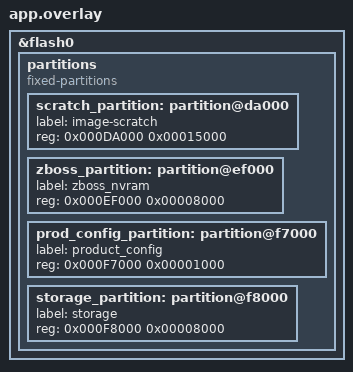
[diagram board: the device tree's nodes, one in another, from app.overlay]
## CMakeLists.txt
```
#
# Copyright (c) 2020 Nordic Semiconductor ASA
#
# SPDX-License-Identifier: LicenseRef-BSD-5-Clause-Nordic
#

cmake_minimum_required(VERSION 3.8)

add_definitions(-DZB_ED_ROLE)

include($ENV{ZEPHYR_BASE}/../nrf/cmake/boilerplate.cmake)
include($ENV{ZEPHYR_BASE}/cmake/app/boilerplate.cmake NO_POLICY_SCOPE)

project("Light Switch")

# NORDIC SDK APP START
target_sources(
  app PRIVATE src/main.c
)
target_sources_ifdef(CONFIG_NUS_CMD
  app PRIVATE src/nus_cmd.c
)
target_include_directories(app PRIVATE include)
# NORDIC SDK APP END
```

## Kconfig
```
#
# Copyright (c) 2020 Nordic Semiconductor ASA
#
# SPDX-License-Identifier: LicenseRef-BSD-5-Clause-Nordic
#

config NUS_CMD
	bool "Enable NUS command service"
	select BT
	select BT_SMP
	select BT_PERIPHERAL
	select BT_GATT_NUS
	select BT_SETTINGS
	select SETTINGS
	help
	  NUS command service

if NUS_CMD_SERVICE

module = NUS_CMD
module-str = NUS command
source "${ZEPHYR_BASE}/subsys/logging/Kconfig.template.log_config"

endif

menu "Zephyr Kernel"
source "Kconfig.zephyr"
endmenu
```

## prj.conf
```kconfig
#
# Copyright (c) 2020 Nordic Semiconductor ASA
#
# SPDX-License-Identifier: LicenseRef-BSD-5-Clause-Nordic
#

CONFIG_NCS_SAMPLES_DEFAULTS=y

CONFIG_UART_INTERRUPT_DRIVEN=y
CONFIG_SERIAL=y
CONFIG_GPIO=y

# Make sure printk is not printing to the UART console
CONFIG_CONSOLE=y
CONFIG_UART_CONSOLE=y

CONFIG_HEAP_MEM_POOL_SIZE=2048

CONFIG_ZIGBEE=y
CONFIG_ZIGBEE_ROLE_END_DEVICE=y

# Enable DK LED and Buttons library
CONFIG_DK_LIBRARY=y

# This example requires more workqueue stack
CONFIG_SYSTEM_WORKQUEUE_STACK_SIZE=2048

# Cryptocell is not supported through CSPRNG driver API: NCSDK-4813
CONFIG_ENTROPY_CC310=n
```

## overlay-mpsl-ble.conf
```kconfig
# Enable NUS command service
CONFIG_NUS_CMD=y

# BLE configuration
CONFIG_BT_DEVICE_NAME="Zigbee_Switch"
CONFIG_BT_DEVICE_APPEARANCE=833
CONFIG_BT_MAX_CONN=1
CONFIG_BT_MAX_PAIRED=1

# Enable multiprotocol
CONFIG_BT_LL_NRFXLIB_DEFAULT=y
```

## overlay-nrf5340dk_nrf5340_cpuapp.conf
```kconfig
#
# Copyright (c) 2020 Nordic Semiconductor ASA
#
# SPDX-License-Identifier: LicenseRef-BSD-5-Clause-Nordic
#
CONFIG_MAIN_STACK_SIZE=2048
CONFIG_MPSL=n

CONFIG_CRYPTO=n
CONFIG_CRYPTO_NRF_ECB=n
CONFIG_ENTROPY_CC3XX=y

CONFIG_TINYCRYPT=y
CONFIG_CTR_DRBG_CSPRNG_GENERATOR=y
CONFIG_ZIGBEE_USE_SOFTWARE_AES=y
```

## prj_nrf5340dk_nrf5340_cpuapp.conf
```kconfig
#
# Copyright (c) 2020 Nordic Semiconductor ASA
#
# SPDX-License-Identifier: LicenseRef-BSD-5-Clause-Nordic
#

CONFIG_NCS_SAMPLES_DEFAULTS=y

CONFIG_UART_INTERRUPT_DRIVEN=y
CONFIG_SERIAL=y
CONFIG_GPIO=y

# Make sure printk is not printing to the UART console
CONFIG_CONSOLE=y
CONFIG_UART_CONSOLE=y

CONFIG_HEAP_MEM_POOL_SIZE=2048
CONFIG_MAIN_STACK_SIZE=2048

CONFIG_ZIGBEE=y
CONFIG_ZIGBEE_ROLE_END_DEVICE=y

# Enable bonding
CONFIG_NVS=y

# Enable DK LED and Buttons library
CONFIG_DK_LIBRARY=y

# This example requires more workqueue stack
CONFIG_SYSTEM_WORKQUEUE_STACK_SIZE=2048

# Use software cryptography on nRF5340
CONFIG_TINYCRYPT=y
CONFIG_CTR_DRBG_CSPRNG_GENERATOR=y
CONFIG_ZIGBEE_USE_SOFTWARE_AES=y

# Enable API for powering down unused RAM parts
CONFIG_RAM_POWER_DOWN_LIBRARY=y

#Networking
CONFIG_MPSL=n
```

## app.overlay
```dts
/* Copyright (c) 2020 Nordic Semiconductor ASA
 *
 * SPDX-License-Identifier: Apache-2.0
 */

 /delete-node/ &scratch_partition;
 /delete-node/ &storage_partition;

 &flash0 {
	partitions {
		compatible = "fixed-partitions";
		#address-cells = <1>;
		#size-cells = <1>;

		scratch_partition: partition@da000 {
			label = "image-scratch";
			reg = <0x000DA000 0x00015000>;
		};
		zboss_partition: partition@ef000 {
			label = "zboss_nvram";
			reg = <0x000EF000 0x00008000>;
		};
		prod_config_partition: partition@f7000 {
			label = "product_config";
			reg = <0x000F7000 0x00001000>;
		};
		storage_partition: partition@f8000 {
			label = "storage";
			reg = <0x000F8000 0x00008000>;
		};
	};
};
```

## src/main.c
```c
/*
 * Copyright (c) 2020 Nordic Semiconductor ASA
 *
 * SPDX-License-Identifier: LicenseRef-BSD-5-Clause-Nordic
 */

/** @file
 * @brief Dimmer switch for HA profile implementation.
 */

#include <zephyr.h>
#include <device.h>
#include <logging/log.h>
#include <settings/settings.h>
#include <dk_buttons_and_leds.h>

#include <zboss_api.h>
#include <zboss_api_addons.h>
#include <zigbee_helpers.h>
#include <zb_error_handler.h>
#include <zb_nrf_platform.h>
#include "zb_mem_config_custom.h"

#if CONFIG_NUS_CMD
#include "nus_cmd.h"

/* LED which indicates that Central is connected */
#define NUS_STATUS_LED            DK_LED1
/* UART command that will turn on found light bulb(s). */
#define COMMAND_ON                "n"
/**< UART command that will turn off found light bulb(s). */
#define COMMAND_OFF               "f"
/**< UART command that will turn toggle found light bulb(s). */
#define COMMAND_TOGGLE            "t"
/**< UART command that will increase brightness of found light bulb(s). */
#define COMMAND_INCREASE          "i"
/**< UART command that will decrease brightness of found light bulb(s). */
#define COMMAND_DECREASE          "d"
#endif

/* Source endpoint used to control light bulb. */
#define LIGHT_SWITCH_ENDPOINT      1
/* Delay between the light switch startup and light bulb finding procedure. */
#define MATCH_DESC_REQ_START_DELAY (2 * ZB_TIME_ONE_SECOND)
/* Timeout for finding procedure. */
#define MATCH_DESC_REQ_TIMEOUT     (5 * ZB_TIME_ONE_SECOND)
/* Find only non-sleepy device. */
#define MATCH_DESC_REQ_ROLE        ZB_NWK_BROADCAST_RX_ON_WHEN_IDLE

/* Do not erase NVRAM to save the network parameters after device reboot or
 * power-off. NOTE: If this option is set to ZB_TRUE then do full device erase
 * for all network devices before running other samples.
 */
#define ERASE_PERSISTENT_CONFIG    ZB_FALSE
/* LED indicating that light switch successfully joind Zigbee network. */
#define ZIGBEE_NETWORK_STATE_LED   DK_LED3
/* LED indicating that light witch found a light bulb to control. */
#define BULB_FOUND_LED             DK_LED4
/* Button ID used to switch on the light bulb. */
#define BUTTON_ON                  DK_BTN1_MSK
/* Button ID used to switch off the light bulb. */
#define BUTTON_OFF                 DK_BTN2_MSK
/* Dim step size - increases/decreses current level (range 0x000 - 0xfe). */
#define DIMM_STEP                  15

/* Transition time for a single step operation in 0.1 sec units.
 * 0xFFFF - immediate change.
 */
#define DIMM_TRANSACTION_TIME      2

/* Time after which the button state is checked again to detect button hold,
 * the dimm command is sent again.
 */
#define BUTTON_LONG_POLL_TMO   ZB_MILLISECONDS_TO_BEACON_INTERVAL(500)

#if !defined ZB_ED_ROLE
#error Define ZB_ED_ROLE to compile light switch (End Device) source code.
#endif

LOG_MODULE_REGISTER(app);

struct light_switch_bulb_params {
	zb_uint8_t  endpoint;
	zb_uint16_t short_addr;
};

struct light_switch_button {
	atomic_t in_progress;
	atomic_t long_poll;
};

struct light_switch_ctx {
	struct light_switch_bulb_params bulb_params;
	struct light_switch_button      button;
};

static struct light_switch_ctx device_ctx;
static zb_uint8_t  attr_zcl_version = ZB_ZCL_VERSION;
static zb_uint8_t  attr_power_source = ZB_ZCL_BASIC_POWER_SOURCE_UNKNOWN;
static zb_uint16_t attr_identify_time;

/* Declare attribute list for Basic cluster. */
ZB_ZCL_DECLARE_BASIC_ATTRIB_LIST(basic_attr_list, &attr_zcl_version,
				 &attr_power_source);

/* Declare attribute list for Identify cluster. */
ZB_ZCL_DECLARE_IDENTIFY_ATTRIB_LIST(identify_attr_list, &attr_identify_time);

/* Declare cluster list for Dimmer Switch device (Identify, Basic, Scenes,
 * Groups, On Off, Level Control).
 * Only clusters Identify and Basic have attributes.
 */
ZB_HA_DECLARE_DIMMER_SWITCH_CLUSTER_LIST(dimmer_switch_clusters,
					 basic_attr_list,
					 identify_attr_list);

/* Declare endpoint for Dimmer Switch device. */
ZB_HA_DECLARE_DIMMER_SWITCH_EP(dimmer_switch_ep,
			       LIGHT_SWITCH_ENDPOINT,
			       dimmer_switch_clusters);

/* Declare application's device context (list of registered endpoints)
 * for Dimmer Switch device.
 */
ZB_HA_DECLARE_DIMMER_SWITCH_CTX(dimmer_switch_ctx, dimmer_switch_ep);

/* Forward declarations */
static void light_switch_button_handler(zb_uint8_t button);
static void find_light_bulb(zb_bufid_t bufid);
static void find_light_bulb_timeout(zb_bufid_t bufid);
static void light_switch_send_on_off(zb_bufid_t bufid, zb_uint16_t on_off);


/**@brief Callback for button events.
 *
 * @param[in]   button_state  Bitmask containing buttons state.
 * @param[in]   has_changed   Bitmask containing buttons that has
 *                            changed their state.
 */
static void button_handler(u32_t button_state, u32_t has_changed)
{
	zb_bool_t on_off;
	zb_ret_t zb_err_code;

	/* Inform default signal handler about user input at the device. */
	user_input_indicate();

	if (device_ctx.bulb_params.short_addr == 0xFFFF) {
		LOG_DBG("No bulb found yet.");
		return;
	}

	switch (has_changed) {
	case BUTTON_ON:
		LOG_DBG("ON - button changed");
		on_off = ZB_TRUE;
		break;
	case BUTTON_OFF:
		LOG_DBG("OFF - button changed");
		on_off = ZB_FALSE;
		break;
	default:
		LOG_DBG("Unhandled button");
		return;
	}

	switch (button_state) {
	case BUTTON_ON:
	case BUTTON_OFF:
		LOG_DBG("Button pressed");
		atomic_set(&device_ctx.button.in_progress, ZB_TRUE);
		zb_err_code = zigbee_schedule_alarm(light_switch_button_handler,
						    button_state,
						    BUTTON_LONG_POLL_TMO);
		if (zb_err_code == RET_OVERFLOW) {
			LOG_WRN("Can't schedule another alarm, queue is full.");
			atomic_set(&device_ctx.button.in_progress, ZB_FALSE);
		} else {
			ZB_ERROR_CHECK(zb_err_code);
		}
		break;
	case 0:
		LOG_DBG("Button released");

		ZB_SCHEDULE_APP_ALARM_CANCEL(light_switch_button_handler,
					     ZB_ALARM_ANY_PARAM);
		atomic_set(&device_ctx.button.in_progress, ZB_FALSE);

		if (atomic_set(&device_ctx.button.long_poll, ZB_FALSE)
		    == ZB_FALSE) {
			/* Allocate output buffer and send on/off command. */
			zb_err_code = zb_buf_get_out_delayed_ext(
				light_switch_send_on_off, on_off, 0);
			ZB_ERROR_CHECK(zb_err_code);
		}
	}
}



/**@brief Function for initializing LEDs and Buttons. */
static void configure_gpio(void)
{
	int err;

	err = dk_buttons_init(button_handler);
	if (err) {
		LOG_ERR("Cannot init buttons (err: %d)", err);
	}

	err = dk_leds_init();
	if (err) {
		LOG_ERR("Cannot init LEDs (err: %d)", err);
	}
}

/**@brief Function for sending ON/OFF requests to the light bulb.
 *
 * @param[in]   bufid    Non-zero reference to Zigbee stack buffer that will be
 *                       used to construct on/off request.
 * @param[in]   on_off   Requested state of the light bulb.
 */
static void light_switch_send_on_off(zb_bufid_t bufid, zb_uint16_t cmd_id)
{
	LOG_INF("Send ON/OFF command: %d", cmd_id);

	ZB_ZCL_ON_OFF_SEND_REQ(bufid,
			       device_ctx.bulb_params.short_addr,
			       ZB_APS_ADDR_MODE_16_ENDP_PRESENT,
			       device_ctx.bulb_params.endpoint,
			       LIGHT_SWITCH_ENDPOINT,
			       ZB_AF_HA_PROFILE_ID,
			       ZB_ZCL_DISABLE_DEFAULT_RESPONSE,
			       cmd_id,
			       NULL);

}

/**@brief Function for sending step requests to the light bulb.
 *
 * @param[in]   bufid        Non-zero reference to Zigbee stack buffer that
 *                           will be used to construct step request.
 * @param[in]   is_step_up   Boolean parameter selecting direction
 *                           of step change.
 */
static void light_switch_send_step(zb_bufid_t bufid, zb_uint16_t is_step_up)
{
	u8_t step_dir = is_step_up ? ZB_ZCL_LEVEL_CONTROL_STEP_MODE_UP :
			ZB_ZCL_LEVEL_CONTROL_STEP_MODE_DOWN;

	LOG_INF("Send step level command: %d", is_step_up);

	ZB_ZCL_LEVEL_CONTROL_SEND_STEP_REQ(bufid,
					   device_ctx.bulb_params.short_addr,
					   ZB_APS_ADDR_MODE_16_ENDP_PRESENT,
					   device_ctx.bulb_params.endpoint,
					   LIGHT_SWITCH_ENDPOINT,
					   ZB_AF_HA_PROFILE_ID,
					   ZB_ZCL_DISABLE_DEFAULT_RESPONSE,
					   NULL,
					   step_dir,
					   DIMM_STEP,
					   DIMM_TRANSACTION_TIME);
}

/**@brief Callback function receiving finding procedure results.
 *
 * @param[in]   bufid   Reference to Zigbee stack buffer used to pass
 *                      received data.
 */
static void find_light_bulb_cb(zb_bufid_t bufid)
{
	/* Get the beginning of the response. */
	zb_zdo_match_desc_resp_t *resp =
			       (zb_zdo_match_desc_resp_t *) zb_buf_begin(bufid);
	/* Get the pointer to the parameters buffer, which stores APS layer
	 * response.
	 */
	zb_apsde_data_indication_t *ind  = ZB_BUF_GET_PARAM(bufid,
						    zb_apsde_data_indication_t);
	zb_uint8_t *match_ep;

	if ((resp->status == ZB_ZDP_STATUS_SUCCESS) &&
		(resp->match_len > 0) &&
		(device_ctx.bulb_params.short_addr == 0xFFFF)) {

		/* Match EP list follows right after response header */
		match_ep = (zb_uint8_t *)(resp + 1);

		/* We are searching for exact cluster, so only 1 EP
		 * may be found.
		 */
		device_ctx.bulb_params.endpoint   = *match_ep;
		device_ctx.bulb_params.short_addr = ind->src_addr;

		LOG_INF("Found bulb addr: %d ep: %d",
			device_ctx.bulb_params.short_addr,
			device_ctx.bulb_params.endpoint);

		zb_ret_t zb_err_code = ZB_SCHEDULE_APP_ALARM_CANCEL(
			find_light_bulb_timeout, ZB_ALARM_ANY_PARAM);
		ZB_ERROR_CHECK(zb_err_code);

		dk_set_led_on(BULB_FOUND_LED);
	}

	if (bufid) {
		zb_buf_free(bufid);
	}
}

/**@brief Function for sending ON/OFF and Level Control find request.
 *
 * @param[in]   bufid   Non-zero reference to Zigbee stack buffer that will be
 *                      used to construct find request.
 */
static void find_light_bulb(zb_bufid_t bufid)
{
	zb_zdo_match_desc_param_t *req;

	/* Initialize pointers inside buffer and reserve space for
	 * zb_zdo_match_desc_param_t request.
	 */
	req = zb_buf_initial_alloc(bufid,
		sizeof(zb_zdo_match_desc_param_t) + (1) * sizeof(zb_uint16_t));

	req->nwk_addr         = MATCH_DESC_REQ_ROLE;
	req->addr_of_interest = MATCH_DESC_REQ_ROLE;
	req->profile_id       = ZB_AF_HA_PROFILE_ID;

	/* We are searching for 2 clusters: On/Off and Level Control Server */
	req->num_in_clusters  = 2;
	req->num_out_clusters = 0;
	req->cluster_list[0]  = ZB_ZCL_CLUSTER_ID_ON_OFF;
	req->cluster_list[1]  = ZB_ZCL_CLUSTER_ID_LEVEL_CONTROL;

	/* Set 0xFFFF to reset short address in order to parse
	 * only one response.
	 */
	device_ctx.bulb_params.short_addr = 0xFFFF;
	(void)zb_zdo_match_desc_req(bufid, find_light_bulb_cb);
}

/**@brief Finding procedure timeout handler.
 *
 * @param[in]   bufid   Reference to Zigbee stack buffer that will be used to
 *                      construct find request.
 */
static void find_light_bulb_timeout(zb_bufid_t bufid)
{
	zb_ret_t zb_err_code;

	if (bufid) {
		LOG_INF("Bulb not found, try again");

		zb_err_code = zigbee_schedule_alarm(find_light_bulb, bufid,
						    MATCH_DESC_REQ_START_DELAY);
		ZB_ERROR_CHECK(zb_err_code);
		zb_err_code = zigbee_schedule_alarm(find_light_bulb_timeout, 0,
							MATCH_DESC_REQ_TIMEOUT);
		ZB_ERROR_CHECK(zb_err_code);
	} else {
		zb_err_code = zb_buf_get_out_delayed(find_light_bulb_timeout);
		ZB_ERROR_CHECK(zb_err_code);
	}
}

/**@brief Callback for detecting button press duration.
 *
 * @param[in]   button   BSP Button that was pressed.
 */
static void light_switch_button_handler(zb_uint8_t button)
{
	zb_ret_t zb_err_code;
	zb_bool_t on_off;

	if (dk_get_buttons() & button) {
		atomic_set(&device_ctx.button.long_poll, ZB_TRUE);
		on_off = (button == BUTTON_ON) ? ZB_TRUE : ZB_FALSE;

		/* Allocate output buffer and send step command. */
		zb_err_code = zb_buf_get_out_delayed_ext(light_switch_send_step,
							 on_off, 0);
		ZB_ERROR_CHECK(zb_err_code);

		zb_err_code = zigbee_schedule_alarm(light_switch_button_handler,
						    button,
						    BUTTON_LONG_POLL_TMO);
		if (zb_err_code == RET_OVERFLOW) {
			LOG_WRN("Can't schedule another alarm, queue is full.");
			atomic_set(&device_ctx.button.in_progress, ZB_FALSE);
		} else {
			ZB_ERROR_CHECK(zb_err_code);
		}
	} else {
		atomic_set(&device_ctx.button.long_poll, ZB_FALSE);
	}
}

/**@brief Zigbee stack event handler.
 *
 * @param[in]   bufid   Reference to the Zigbee stack buffer
 *                      used to pass signal.
 */
void zboss_signal_handler(zb_bufid_t bufid)
{
	zb_zdo_app_signal_hdr_t    *sig_hndler = NULL;
	zb_zdo_app_signal_type_t    sig = zb_get_app_signal(bufid, &sig_hndler);
	zb_ret_t                    status = ZB_GET_APP_SIGNAL_STATUS(bufid);
	zb_ret_t                    zb_err_code;

	/* Update network status LED */
	zigbee_led_status_update(bufid, ZIGBEE_NETWORK_STATE_LED);

	switch (sig) {
	case ZB_BDB_SIGNAL_DEVICE_REBOOT:
	/* fall-through */
	case ZB_BDB_SIGNAL_STEERING:
		/* Call default signal handler. */
		ZB_ERROR_CHECK(zigbee_default_signal_handler(bufid));
		if (status == RET_OK) {
			/* Check the light device address */
			if (device_ctx.bulb_params.short_addr == 0xFFFF) {
				zb_err_code = zigbee_schedule_alarm(
					find_light_bulb, bufid,
					MATCH_DESC_REQ_START_DELAY);
				ZB_ERROR_CHECK(zb_err_code);
				zb_err_code = zigbee_schedule_alarm(
					find_light_bulb_timeout, 0,
					MATCH_DESC_REQ_TIMEOUT);
				ZB_ERROR_CHECK(zb_err_code);
				/* Do not free buffer - it will be reused by
				 * find_light_bulb callback.
				 */
				bufid = 0;
			}
		}
		break;
	default:
		/* Call default signal handler. */
		ZB_ERROR_CHECK(zigbee_default_signal_handler(bufid));
		break;
	}

	if (bufid) {
		zb_buf_free(bufid);
	}
}

#if CONFIG_NUS_CMD

static void turn_on_cmd(struct k_work *item)
{
	ARG_UNUSED(item);
	zb_buf_get_out_delayed_ext(light_switch_send_on_off,
				   ZB_ZCL_CMD_ON_OFF_ON_ID, 0);
}

static void turn_off_cmd(struct k_work *item)
{
	ARG_UNUSED(item);
	zb_buf_get_out_delayed_ext(light_switch_send_on_off,
				   ZB_ZCL_CMD_ON_OFF_OFF_ID, 0);
}

static void toggle_cmd(struct k_work *item)
{
	ARG_UNUSED(item);
	zb_buf_get_out_delayed_ext(light_switch_send_on_off,
				   ZB_ZCL_CMD_ON_OFF_TOGGLE_ID, 0);
}

static void increase_cmd(struct k_work *item)
{
	ARG_UNUSED(item);
	zb_buf_get_out_delayed_ext(light_switch_send_step,
				   ZB_ZCL_LEVEL_CONTROL_STEP_MODE_UP, 0);
}

static void decrease_cmd(struct k_work *item)
{
	ARG_UNUSED(item);
	zb_buf_get_out_delayed_ext(light_switch_send_step,
				   ZB_ZCL_LEVEL_CONTROL_STEP_MODE_DOWN, 0);
}

static void on_nus_connect(struct k_work *item)
{
	ARG_UNUSED(item);
	dk_set_led_on(NUS_STATUS_LED);
}

static void on_nus_disconnect(struct k_work *item)
{
	ARG_UNUSED(item);
	dk_set_led_off(NUS_STATUS_LED);
}

static nus_entry_t commands[] = {
	NUS_COMMAND(COMMAND_ON, turn_on_cmd),
	NUS_COMMAND(COMMAND_OFF, turn_off_cmd),
	NUS_COMMAND(COMMAND_TOGGLE, toggle_cmd),
	NUS_COMMAND(COMMAND_INCREASE, increase_cmd),
	NUS_COMMAND(COMMAND_DECREASE, decrease_cmd),
	NUS_COMMAND(NULL, NULL),
};

#endif

void main(void)
{
	LOG_INF("Starting ZBOSS Light Switch example");

	/* Initialize. */
	configure_gpio();

	zigbee_erase_persistent_storage(ERASE_PERSISTENT_CONFIG);
	zb_set_ed_timeout(ED_AGING_TIMEOUT_64MIN);
	zb_set_keepalive_timeout(ZB_MILLISECONDS_TO_BEACON_INTERVAL(3000));

	/* Initialize application context structure. */
	memset(&device_ctx, 0, sizeof(struct light_switch_ctx));

	/* Set default bulb short_addr. */
	device_ctx.bulb_params.short_addr = 0xFFFF;

	/* Register dimmer switch device context (endpoints). */
	ZB_AF_REGISTER_DEVICE_CTX(&dimmer_switch_ctx);

	/* Start Zigbee default thread */
	zigbee_enable();

#if CONFIG_NUS_CMD
	/* Initalize NUS command service */
	nus_cmd_init(on_nus_connect, on_nus_disconnect, commands);
#endif

	LOG_INF("ZBOSS Light Switch example started");

	while (1) {
		k_sleep(K_FOREVER);
	}
}
```

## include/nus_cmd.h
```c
/*
 * Copyright (c) 2020 Nordic Semiconductor ASA
 *
 * SPDX-License-Identifier: LicenseRef-BSD-5-Clause-Nordic
 */

/**
 * @file nus_cmd.h
 *
 * @brief APIs for NUS Command Service.
 */

#ifndef __NUS_CMD_H__
#define __NUS_CMD_H__

/** @brief Type indicates function called when Bluetooth LE connection
 *         is established.
 *
 * @param[in] item pointer to work item.
 */
typedef void (*nus_connection_cb_t)(struct k_work *item);

/** @brief Type indicates function called when Bluetooth LE connection is ended.
 *
 * @param[in] item pointer to work item.
 */
typedef void (*nus_disconnection_cb_t)(struct k_work *item);

/** @brief NUS command entry.
 */
typedef struct nus_entry_s {
	const char *cmd;        /**< Command string */
	struct k_work work;     /**< Command work item */
} nus_entry_t;

/**@brief Macro to initialise (bind) command string to work handler.
 */
#define NUS_COMMAND(_cmd, _handler)		      \
	{					      \
		.work = Z_WORK_INITIALIZER(_handler), \
		.cmd = _cmd,			      \
	}					      \

/**@brief Function to initialise NUS Command service.
 *
 * @param[in] on_connect Callback that will be called when central connects to
 *			 the NUS service.
 * @param[in] on_disconnect Callback that will be called when BLE central
 *			    disconnects from the NUS service.
 * @param[in] command_set   A pointer to an array with NUS commands.
 */
void nus_cmd_init(nus_connection_cb_t on_connect,
		  nus_disconnection_cb_t on_disconnect,
		  nus_entry_t *command_set);

#endif
```

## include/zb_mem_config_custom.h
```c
/*
 * Copyright (c) 2020 Nordic Semiconductor ASA
 *
 * SPDX-License-Identifier: LicenseRef-BSD-5-Clause-Nordic
 */

#ifndef ZB_MEM_CONFIG_CUSTOM_H
#define ZB_MEM_CONFIG_CUSTOM_H 1


#define ZB_CONFIG_ROLE_ZED
/*#define ZB_CONFIG_ROLE_ZR*/
/*#define ZB_CONFIG_ROLE_ZED*/

/*#define ZB_CONFIG_OVERALL_NETWORK_SIZE 128*/
/*#define ZB_CONFIG_OVERALL_NETWORK_SIZE 32*/
#define ZB_CONFIG_OVERALL_NETWORK_SIZE 16

/*#define ZB_CONFIG_HIGH_TRAFFIC*/
/*#define ZB_CONFIG_MODERATE_TRAFFIC*/
/**
 * Light routing and application traffic from/to that device.
 */
#define ZB_CONFIG_LIGHT_TRAFFIC

/*#define ZB_CONFIG_APPLICATION_COMPLEX*/
/*#define ZB_CONFIG_APPLICATION_MODERATE*/
/**
 * Simple user's application at that device: not too many relations
 * to other devices.
 */
#define ZB_CONFIG_APPLICATION_SIMPLE

/**
 * Now common logic derives numerical parameters from the defined
 * configuration.
 */
#include "zb_mem_config_common.h"

/**
 * Now if you REALLY know what you do, you can study zb_mem_config_common.h
 * and redefine some configuration parameters, like:
 */
#undef ZB_CONFIG_SCHEDULER_Q_SIZE
#define ZB_CONFIG_SCHEDULER_Q_SIZE 24


/* Memory context definitions */
#include "zb_mem_config_context.h"

#endif /* ZB_MEM_CONFIG_CUSTOM_H */
```

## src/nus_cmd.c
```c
/*
 * Copyright (c) 2020 Nordic Semiconductor ASA
 *
 * SPDX-License-Identifier: LicenseRef-BSD-5-Clause-Nordic
 */
#include <zephyr.h>
#include <bluetooth/gatt.h>
#include <bluetooth/hci.h>
#include <bluetooth/uuid.h>
#include <bluetooth/services/nus.h>
#include <logging/log.h>
#include <settings/settings.h>

#include "nus_cmd.h"

LOG_MODULE_REGISTER(nus_cmd);

#define DEVICE_NAME        CONFIG_BT_DEVICE_NAME
#define DEVICE_NAME_LEN    (sizeof(DEVICE_NAME) - 1)

static void connected(struct bt_conn *conn, u8_t err);
static void disconnected(struct bt_conn *conn, u8_t reason);
static void auth_passkey_display(struct bt_conn *conn, unsigned int passkey);
static void auth_cancel(struct bt_conn *conn);
static void pairing_confirm(struct bt_conn *conn);
static void pairing_complete(struct bt_conn *conn, bool bonded);
static void pairing_failed(struct bt_conn *conn, enum bt_security_err reason);
static void __attribute__((unused))
security_changed(struct bt_conn *conn, bt_security_t level,
		 enum bt_security_err err);

static struct bt_conn_auth_cb conn_auth_callbacks = {
	.passkey_display = auth_passkey_display,
	.cancel = auth_cancel,
	.pairing_confirm = pairing_confirm,
	.pairing_complete = pairing_complete,
	.pairing_failed = pairing_failed
};

static struct bt_conn_cb conn_callbacks = {
	.connected = connected,
	.disconnected = disconnected,
	COND_CODE_1(CONFIG_BT_SMP, (.security_changed = security_changed), ())
};

static const struct bt_data ad[] = {
	BT_DATA_BYTES(BT_DATA_FLAGS, (BT_LE_AD_GENERAL | BT_LE_AD_NO_BREDR)),
	BT_DATA(BT_DATA_NAME_COMPLETE, DEVICE_NAME, DEVICE_NAME_LEN),
};

static const struct bt_data sd[] = {
	BT_DATA_BYTES(BT_DATA_UUID128_ALL, NUS_UUID_SERVICE),
};

static struct k_work on_connect_work;
static struct k_work on_disconnect_work;
static struct bt_conn *current_conn;
static nus_entry_t *nus_commands;

static void connected(struct bt_conn *conn, u8_t err)
{
	if (err) {
		LOG_ERR("Connection failed (err %u)", err);
		return;
	}

	LOG_INF("Connected");
	current_conn = bt_conn_ref(conn);

	k_work_submit(&on_connect_work);
}

static void disconnected(struct bt_conn *conn, u8_t reason)
{
	LOG_INF("Disconnected (reason %u)", reason);

	if (current_conn) {
		bt_conn_unref(current_conn);
		current_conn = NULL;

		k_work_submit(&on_disconnect_work);
	}
}

static char *ble_addr(struct bt_conn *conn)
{
	static char addr[BT_ADDR_LE_STR_LEN];

	bt_addr_le_to_str(bt_conn_get_dst(conn), addr, sizeof(addr));

	return addr;
}

static void __attribute__((unused))
security_changed(struct bt_conn *conn, bt_security_t level,
		 enum bt_security_err err)
{
	char *addr = ble_addr(conn);

	if (!err) {
		LOG_INF("Security changed: %s level %u", log_strdup(addr),
			level);
	} else {
		LOG_INF("Security failed: %s level %u err %d", log_strdup(addr),
			level, err);
	}
}

static void auth_passkey_display(struct bt_conn *conn, unsigned int passkey)
{
	char *addr = ble_addr(conn);

	/* Logging this in the production code is unsafe */
	LOG_INF("Passkey for %s: %06u", log_strdup(addr), passkey);
}

static void auth_cancel(struct bt_conn *conn)
{
	char *addr = ble_addr(conn);

	LOG_INF("Pairing cancelled: %s", log_strdup(addr));
}

static void pairing_confirm(struct bt_conn *conn)
{
	char *addr = ble_addr(conn);

	bt_conn_auth_pairing_confirm(conn);

	LOG_INF("Pairing confirmed: %s", log_strdup(addr));
}

static void pairing_complete(struct bt_conn *conn, bool bonded)
{
	char *addr = ble_addr(conn);

	LOG_INF("Pairing completed: %s, bonded: %d", log_strdup(addr), bonded);
}

static void pairing_failed(struct bt_conn *conn, enum bt_security_err reason)
{
	char *addr = ble_addr(conn);

	LOG_INF("Pairing failed conn: %s, reason %d", log_strdup(addr), reason);
}

static int ble_utils_init(struct bt_gatt_nus_cb *nus_clbs,
			  nus_connection_cb_t on_connect,
			  nus_disconnection_cb_t on_disconnect)
{
	int ret;

	k_work_init(&on_connect_work, on_connect);
	k_work_init(&on_disconnect_work, on_disconnect);

	bt_conn_cb_register(&conn_callbacks);

	if (IS_ENABLED(CONFIG_BT_SMP)) {
		bt_conn_auth_cb_register(&conn_auth_callbacks);
	}

	ret = bt_enable(NULL);
	if (ret) {
		LOG_ERR("Bluetooth initialization failed (error: %d)", ret);
		goto end;
	}

	LOG_INF("Bluetooth initialized");

	if (IS_ENABLED(CONFIG_SETTINGS)) {
		settings_load();
	}

	ret = bt_gatt_nus_init(nus_clbs);
	if (ret) {
		LOG_ERR("Failed to initialize UART service (error: %d)", ret);
		goto end;
	}

	ret = bt_le_adv_start(BT_LE_ADV_CONN, ad, ARRAY_SIZE(ad), sd,
			      ARRAY_SIZE(sd));
	if (ret) {
		LOG_ERR("Advertising failed to start (error: %d)", ret);
		goto end;
	}

end:
	return ret;
}

static void nus_command_handler(struct bt_conn *conn,
				const u8_t *const data, u16_t length)
{
	LOG_HEXDUMP_DBG(data, length, "NUS recv:");

	for (nus_entry_t *p = nus_commands; p->cmd != NULL; p++) {
		if ((length >= strlen(p->cmd)) &&
		    (!strncmp(p->cmd, (const char *)data, strlen(p->cmd)))) {
			LOG_DBG("Matched cmd: %s", log_strdup(p->cmd));
			k_work_submit(&p->work);
			return;
		}
	}

	LOG_HEXDUMP_WRN(data, length, "Command unrecognized");
}

void nus_cmd_init(nus_connection_cb_t on_connect,
		  nus_disconnection_cb_t on_disconnect,
		  nus_entry_t *command_set)
{
	struct bt_gatt_nus_cb nus_clbs = {
		.received_cb = nus_command_handler,
		.sent_cb = NULL,
	};

	nus_commands = command_set;
	ble_utils_init(&nus_clbs, on_connect, on_disconnect);
}
```
